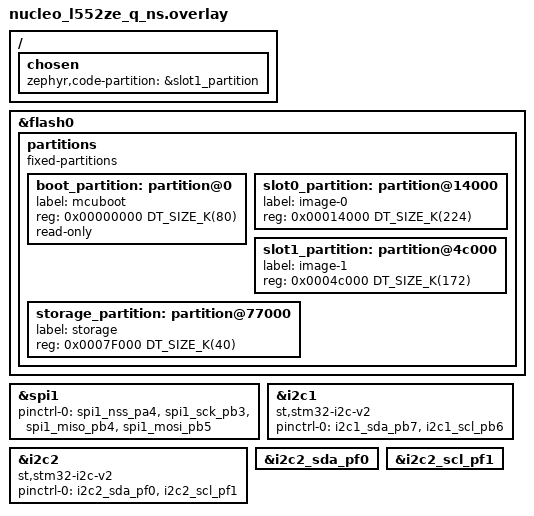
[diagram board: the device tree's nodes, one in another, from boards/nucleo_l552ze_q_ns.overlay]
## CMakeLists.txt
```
cmake_minimum_required(VERSION 3.20.0)
find_package(Zephyr REQUIRED HINTS $ENV{ZEPHYR_BASE})
project(trusted_delivery)

if(DEFINED UNTRUSTED)
    message("#################################################")
    message("#################################################")
    message(FATAL_ERROR "Building untrusted setup not supported for this sample")
    message("#################################################")
    message("#################################################")
    #    target_compile_definitions(app PUBLIC UNTRUSTED)
    #
    #    # OLED DRIVER
    #    target_include_directories(app PRIVATE driver/oled_driver )
    #    target_include_directories(app PRIVATE driver/oled_driver/Config )
    #    target_include_directories(app PRIVATE driver/oled_driver/OLED )
    #    target_include_directories(app PRIVATE driver/oled_driver/GUI )
    #    target_include_directories(app PRIVATE driver/oled_driver/Example )
    #    file(GLOB_RECURSE oled_driver_sources CONFIGURE_DEPENDS driver/oled_driver/*.c)
    #
    #    target_include_directories(app PRIVATE src/ )
    #
    #    # included because driver code is full of these warnings
    #    target_compile_options(app PRIVATE -Wno-missing-braces)
    #    target_compile_options(app PRIVATE -Wno-comment)
    #
    #    target_sources(app PRIVATE
    #            ${oled_driver_sources}
    #            src/main.c
    #            trusted_peripheral/trusted_peripheral.c
    #    )
else()
    message("#################################################")
    message("#################################################")
    message(STATUS "Building trusted setup")
    message("#################################################")
    message("#################################################")
    target_compile_definitions(app PUBLIC TRUSTED)

    # NOTE force test flash layout for more flash memory
    set_property(TARGET zephyr_property_target
                 APPEND PROPERTY TFM_CMAKE_OPTIONS
                 -DTFM_S_REG_TEST=ON
    )

    target_sources(app PRIVATE
            src/main.c
            src/trusted_peripheral_ns.c
    )

    # secure partition
    get_target_property(TFM_BINARY_DIR tfm TFM_BINARY_DIR)
    configure_file(
      ${CMAKE_CURRENT_LIST_DIR}/trusted_peripheral/tfm_manifest_list.yaml.in
      ${CMAKE_CURRENT_BINARY_DIR}/trusted_peripheral/tfm_manifest_list.yaml
    )
    
    set_property(TARGET zephyr_property_target
      APPEND PROPERTY TFM_CMAKE_OPTIONS
      -DTFM_EXTRA_MANIFEST_LIST_FILES=${CMAKE_CURRENT_BINARY_DIR}/trusted_peripheral/tfm_manifest_list.yaml
      -DTFM_EXTRA_PARTITION_PATHS=${CMAKE_CURRENT_LIST_DIR}/trusted_peripheral
    )
    
    # include folder that has tfm_api.h
    target_include_directories(app PRIVATE
      $<TARGET_PROPERTY:tfm,TFM_BINARY_DIR>/install/interface/include
    )
    
    target_compile_definitions(app
        PRIVATE TFM_PARTITION_TRUSTED_PERIPHERAL
    )
endif()
```

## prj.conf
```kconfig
# NOTE a combination of these enables "%f" for printk
CONFIG_SHELL=y
CONFIG_SENSOR_SHELL=y
CONFIG_SENSOR=y

#
# PARTITION
#
CONFIG_BUILD_WITH_TFM=y
CONFIG_TFM_PROFILE_TYPE_NOT_SET=y

# The TF-M build system produces an interface source file for accessing
# connection based services. Select this option when TF-M service models
# requires this source file. Note: This is an auto-generated configuration in
# the TF-M build system. When this option is not enabled in the TF-M build
# system this will result in compilation error.
#CONFIG_TFM_CONNECTION_BASED_SERVICE_API=y

# NOTE: larger stack size is needed. Otherwise some functions in the OLED
# driver can never be called and the board is just stuck (untrusted) or stuck
# in a boot loop (trusted)
CONFIG_MAIN_STACK_SIZE=4096


# FORCE SFN
CONFIG_TFM_IPC=n
CONFIG_TFM_SFN=y
```

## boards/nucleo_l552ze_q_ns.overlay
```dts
/ {
	chosen {
		zephyr,code-partition = &slot1_partition;
	};
};

&flash0 {

	partitions {
		compatible = "fixed-partitions";
		#address-cells = <1>;
		#size-cells = <1>;

		boot_partition: partition@0 {
			label = "mcuboot";
			reg = <0x00000000 DT_SIZE_K(80)>;
			read-only;
		};
		/* Secure image primary slot */
		slot0_partition: partition@14000 {
			label = "image-0";
			reg = <0x00014000 DT_SIZE_K(224)>;
		};
		/* Non-secure image primary slot */
		slot1_partition: partition@4c000 {
			label = "image-1";
			reg = <0x0004c000 DT_SIZE_K(172)>;
		};
		/*
		 * The flash starting at 0x7F000 and ending at
		 * 0x80000 is reserved for the application.
		 */
		storage_partition: partition@77000 {
			label = "storage";
			reg = <0x0007F000 DT_SIZE_K(40)>;
		};
	};
};

&spi1 {
    /* pinctrl-0 = < &spi1_nss_pa4 &spi1_sck_pa5 &spi1_miso_pa6 &spi1_mosi_pa7 >; */
	pinctrl-0 = < &spi1_nss_pa4 &spi1_sck_pb3 &spi1_miso_pb4 &spi1_mosi_pb5 >;
};

&i2c1 {
			compatible = "st,stm32-i2c-v2";
            status = "okay";
            /* sda-pin = <26>; */
            /* scl-pin = <27>; */

            /* pinctrl-0 = <>; */
            pinctrl-0 = <&i2c1_sda_pb7 &i2c1_scl_pb6>;
            pinctrl-names = "default";
};

&i2c2 {
			compatible = "st,stm32-i2c-v2";
            status = "okay";
            /* sda-pin = <26>; */
            /* scl-pin = <27>; */

            pinctrl-0 = <&i2c2_sda_pf0 &i2c2_scl_pf1>;
            pinctrl-names = "default";
};

&i2c2_sda_pf0 {
            /* /delete-property/ bias-pull-up;     */
            /* /delete-property/ drive-open-drain; */
};

&i2c2_scl_pf1 {
            /* /delete-property/ bias-pull-up;     */
            /* /delete-property/ drive-open-drain; */
            /* bias-disable */
            /* bias-pull-up */
            /* bias-pull-down */
            /* drive-push-pull */
            /* drive-open-drain */
            /* output-low */
            /* output-high */
};
```

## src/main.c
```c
#include <zephyr/kernel.h>
#include <zephyr/device.h>
#include <zephyr/drivers/gpio.h>
#include <zephyr/drivers/i2c.h>

#ifdef UNTRUSTED
#else
  #include <tfm_ns_interface.h>
#endif

#include "trusted_peripheral.h"

int main(void)
{
    tp_mac_t mac = {0};

    for (;;)
    {
        // uint32_t tick_begin = HAL_GetTick(); /* TODO by default the tick increments for every ms.
        //                                       * is that accurate enough to measure performance ? */

        float sensor_temperature = 0.0f;
        float sensor_humidity    = 0.0f;

        /* use our trusted peripheral api */
        psa_status_t ret = tp_sensor_data_get(&sensor_temperature, &sensor_humidity, &mac, sizeof(tp_mac_t));
        if (ret != 0) { printk("Getting sensor data failed with status: %i\n", ret); }

        // uint32_t tick_end = HAL_GetTick();
        // printk("(%u ms) ", tick_end - tick_begin);
        printk("Temp: %f ", sensor_temperature);
        printk("Humidity: %f\n", sensor_humidity);

        printk("HASH: ");
        for (int i = 0; i < 32; i++)
        {
            printk("%02x", mac.hash[i]);
        }
        printk("\n");

        printk("SIGN: ");
        for (int i = 0; i < 256; i++)
        {
            printk("%02x", mac.sign[i]);
        }
        printk("\n");

        k_sleep(K_MSEC(10000000)); // for some reason the emulated mps2_an521 is not tuned right
    }

    return 0;
}
```

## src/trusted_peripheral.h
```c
#ifdef UNTRUSTED
  #include <stdint.h> // for int32_t
  #include <stddef.h> // for size_t
  typedef int32_t psa_status_t;
#else
  #include "tfm_api.h"
#endif

#define MAC_HASH_SIZE 64  // == PSA_HASH_MAX_SIZE
#define MAC_SIGN_SIZE 512 // == PSA_SIGNATURE_MAX_SIZE
typedef struct {
    uint8_t hash[MAC_HASH_SIZE];  /* lets assume our data packet fits into this buffer */
    uint8_t sign[MAC_SIGN_SIZE];  /* lets assume our data packet fits into this buffer */
} tp_mac_t;

psa_status_t tp_sensor_data_get(float* temp, float* humidity, void* mac, size_t mac_size);
```

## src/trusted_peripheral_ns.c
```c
#include "trusted_peripheral.h"

/*
** Implements the tp_api to pass execution over to the secure side over an IPC mechanism
*/

#include <stdio.h>

#include <tfm_ns_interface.h>

#if defined(CONFIG_TFM_IPC)
#include "psa/client.h"
#endif
#include "psa_manifest/sid.h"

psa_status_t tp_sensor_data_get(float* temp, float* humidity, void* mac, size_t mac_size)
{
    psa_status_t status;

    psa_invec  in_vec[]  = { { .base = NULL, .len = 0 } }; // input parameter
    psa_outvec out_vec[] = {
        { .base = temp,     .len = sizeof(temp)   },
        { .base = humidity, .len = sizeof(humidity)   },
        { .base = mac,      .len = mac_size   }, // causes psa error
    }; // output parameter

#if defined(CONFIG_TFM_IPC)
    printf("USING IPC: ");

    psa_handle_t handle;
    handle = psa_connect(TFM_TP_SENSOR_DATA_GET_SID, TFM_TP_SENSOR_DATA_GET_VERSION);

    if (!PSA_HANDLE_IS_VALID(handle)) { return PSA_ERROR_GENERIC_ERROR; }

    status = psa_call(handle, PSA_IPC_CALL, in_vec, IOVEC_LEN(in_vec), out_vec, IOVEC_LEN(out_vec));

    psa_close(handle);
#else
    printf("USING SFN: ");

    status = psa_call(TFM_TP_SENSOR_DATA_GET_HANDLE, 0, in_vec, IOVEC_LEN(in_vec), out_vec, IOVEC_LEN(out_vec));
#endif

    return status;
}
```
